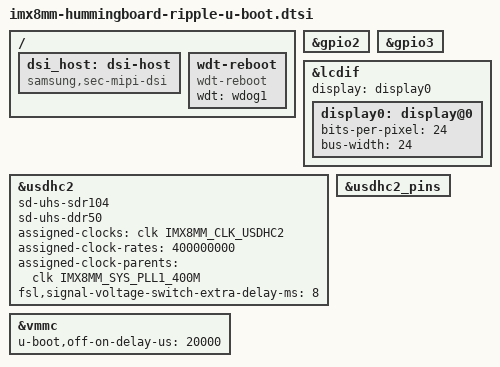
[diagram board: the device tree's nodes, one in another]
// SPDX-License-Identifier: GPL-2.0+
/*
 * Copyright 2025 Josua Mayer <josua@solid-run.com>
 */

#include "imx8mm-sr-som-u-boot.dtsi"

/ {
	dsi_host: dsi-host {
		compatible = "samsung,sec-mipi-dsi";
		status = "okay";
	};

	wdt-reboot {
		compatible = "wdt-reboot";
		wdt = <&wdog1>;
		bootph-pre-ram;
	};
};

&gpio2 {
	bootph-pre-ram;
};

&gpio3 {
	bootph-pre-ram;
};

&lcdif {
	display = <&display0>;
	status = "okay";

	display0: display@0 {
		bits-per-pixel = <24>;
		bus-width = <24>;
	};
};

&usdhc2 {
	bootph-pre-ram;
	sd-uhs-sdr104;
	sd-uhs-ddr50;
	assigned-clocks = <&clk IMX8MM_CLK_USDHC2>;
	assigned-clock-rates = <400000000>;
	assigned-clock-parents = <&clk IMX8MM_SYS_PLL1_400M>;
	fsl,signal-voltage-switch-extra-delay-ms = <8>;
};

&usdhc2_pins {
	bootph-pre-ram;
};

&vmmc {
	u-boot,off-on-delay-us = <20000>;
	bootph-pre-ram;
};
